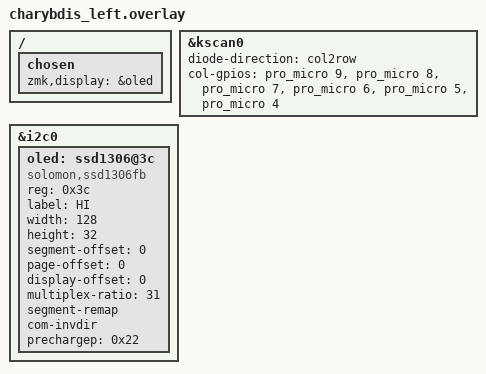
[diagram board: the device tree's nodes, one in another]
/*
 * Copyright (c) 2022 Duccio Breschi
 *
 * SPDX-License-Identifier: MIT
 */

#include "charybdis.dtsi"

&kscan0 {
    diode-direction = "col2row";
    col-gpios
         = <&pro_micro 9 (GPIO_ACTIVE_HIGH)> // COL0
        , <&pro_micro 8 (GPIO_ACTIVE_HIGH)> // COL1
        , <&pro_micro 7 (GPIO_ACTIVE_HIGH)> // COL2
        , <&pro_micro 6 (GPIO_ACTIVE_HIGH)> // COL3
	    , <&pro_micro 5 (GPIO_ACTIVE_HIGH)> // COL4
        , <&pro_micro 4 (GPIO_ACTIVE_HIGH)> // COL5
    ;
};

/ {
    chosen {
        zmk,display = &oled;
    };
};

&i2c0 {
    oled: ssd1306@3c {
        compatible = "solomon,ssd1306fb";
        reg = <0x3c>;
        label = "HI";
        width = <128>;
        height = <32>;
        segment-offset = <0>;
        page-offset = <0>;
        display-offset = <0>;
        multiplex-ratio = <31>;
        segment-remap;
        com-invdir;
        prechargep = <0x22>;
    };
};

